# PT32x063xx register map
File version: 0.1
Registers are 32-bit, read-write, reset 0x0 unless marked. A register's access mark holds for its fields unless they carry their own. Offsets are from the block's base; [hi:lo] are bit positions.

## I2C0 — Inter Integrated Circuit
Base 0x40005400
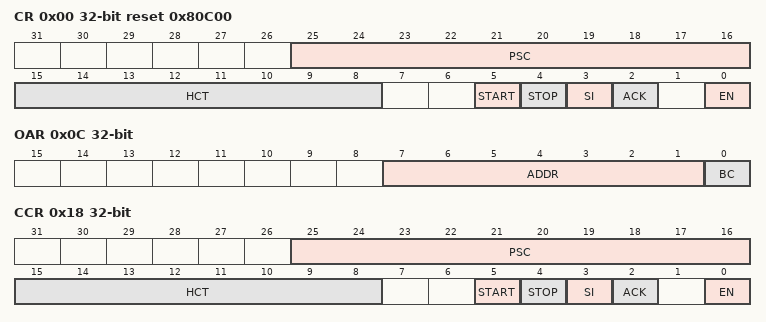
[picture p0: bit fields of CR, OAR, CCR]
0x00 CR access per field reset 0x80C00 — Control Register
  [25:16] PSC rw — Baud rate control
  [15:8] HCT rw — High level detection coefficient of time
  [5] START rw — Start generation
  [4] STOP rw — Stop generation
  [3] SI ro — I2C status flag
  [2] ACK rw — Acknowledge enable
  [0] EN rw — I2C enable
0x04 SR ro reset 0x1F — Status Register
  [4:0] SR — I2C bus status
0x08 DR — Data Register
  [7:0] DR — I2C data
0x0C OAR — Own Address Register
  [7:1] ADDR — I2C addr
  [0] BC — Broadcast response control
0x18 CCR wo — Control Clear Register
  [25:16] PSC — Clear prescaler
  [15:8] HCT — Clear high level detection time
  [5] START — Clear start generation
  [4] STOP — Clear stop generation
  [3] SI — Clear I2C interrupt flag
  [2] ACK — Clear Acknowledge control
  [0] EN — I2C disable

## UART0 — Universal Asynchronous Receiver Transmitter
Base 0x40004400
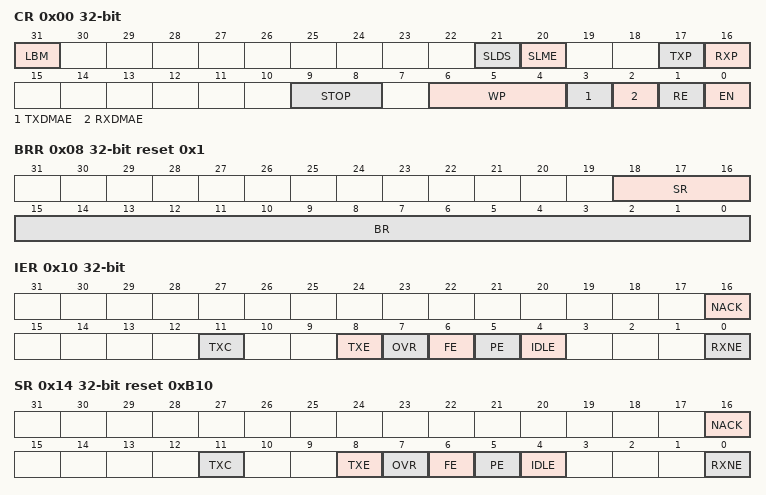
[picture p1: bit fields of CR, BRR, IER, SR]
0x00 CR — Control Register
  [31] LBM — loopback mode
  [21] SLDS — Single-line direction setting
  [20] SLME — Single-line mode enable
  [17] TXP — Transmitter polarity control
  [16] RXP — Receiver polarity control
  [9:8] STOP — Stop bit length
  [6:4] WP — Word length and parity config
  [3] TXDMAE — Tx DMA request enable
  [2] RXDMAE — Rx DMA request enable
  [1] RE — Receive enable
  [0] EN — UART enable
0x08 BRR reset 0x1 — Baud Rate Register
  [18:16] SR — Sample rate
  [15:0] BR — Baud rate control
0x10 IER — Interrupt Enable Register
  [16] NACK — Receive NACK interrupt enable
  [11] TXC — Transmit complete interrupt enable
  [8] TXE — Transmit FIFO empty interrupt enable
  [7] OVR — Receive/Receive-FIFO overflow interrupt enable
  [6] FE — frame error interrupt enable
  [5] PE — parity error interrupt enable
  [4] IDLE — Idle timeout interrupt enable
  [0] RXNE — Receive/Receive-FIFO not empty interrupt enable
0x14 SR reset 0xB10 — Status Register
  [16] NACK — Receive NACK flag
  [11] TXC ro — Transmit complete flag
  [8] TXE ro — Transmit/Transmit-FIFO empty flag
  [7] OVR — Receive/Receive-FIFO overflow flag
  [6] FE — Frame error flag
  [5] PE — Parity error flag
  [4] IDLE — Idle overtime interrupt enable
  [0] RXNE — Receive/Receive-FIFO not empty flag
0x18 DR — Data Register
  [8:0] DR — UART data
0x20 FITR — Frame Interval Time Configuration Register
  [7:0] FIT — Frame interval time
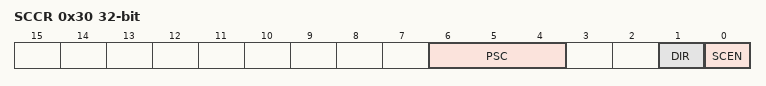
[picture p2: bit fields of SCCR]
0x30 SCCR — Smart Card Control Register
  [6:4] PSC — Prescaler value
  [1] DIR — Data transfer direction control
  [0] SCEN — Smart card mode enable

## UART1 — Universal Asynchronous Receiver Transmitter
Base 0x40013800
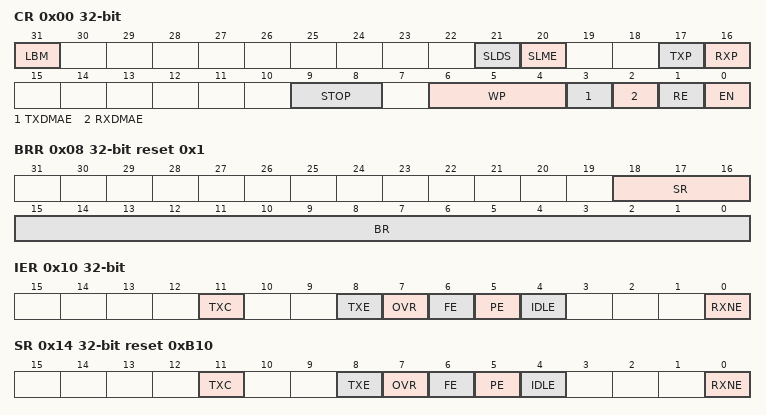
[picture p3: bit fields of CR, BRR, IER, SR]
0x00 CR — Control Register
  [31] LBM — loopback mode
  [21] SLDS — Single-line direction setting
  [20] SLME — Single-line mode enable
  [17] TXP — Transmitter polarity control
  [16] RXP — Receiver polarity control
  [9:8] STOP — Stop bit length
  [6:4] WP — Word length and parity config
  [3] TXDMAE — Tx DMA request enable
  [2] RXDMAE — Rx DMA request enable
  [1] RE — Receive enable
  [0] EN — UART enable
0x08 BRR reset 0x1 — Baud Rate Register
  [18:16] SR — Sample rate
  [15:0] BR — Baud rate control
0x10 IER — Interrupt Enable Register
  [11] TXC — Transmit complete interrupt enable
  [8] TXE — Transmit FIFO empty interrupt enable
  [7] OVR — Receive/Receive-FIFO overflow interrupt enable
  [6] FE — frame error interrupt enable
  [5] PE — parity error interrupt enable
  [4] IDLE — Idle timeout interrupt enable
  [0] RXNE — Receive/Receive-FIFO not empty interrupt enable
0x14 SR reset 0xB10 — Status Register
  [11] TXC ro — Transmit complete flag
  [8] TXE ro — Transmit/Transmit-FIFO empty flag
  [7] OVR — Receive/Receive-FIFO overflow flag
  [6] FE — Frame error flag
  [5] PE — Parity error flag
  [4] IDLE — Idle overtime interrupt enable
  [0] RXNE — Receive/Receive-FIFO not empty flag
0x18 DR — Data Register
  [8:0] DR — UART data
0x20 FITR — Frame Interval Time Configuration Register
  [7:0] FIT — Frame interval time
